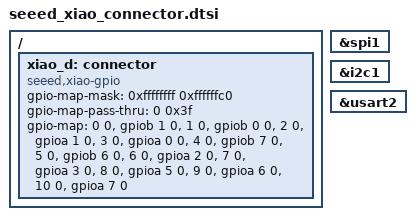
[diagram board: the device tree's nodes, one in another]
/*
 * SPDX-FileCopyrightText: Copyright (c) 2026 Perry Naseck, MIT Media Lab <pnaseck@media.mit.edu>
 * SPDX-License-Identifier: Apache-2.0
 */

/ {
	xiao_d: connector {
		compatible = "seeed,xiao-gpio";
		#gpio-cells = <2>;
		gpio-map-mask = <0xffffffff 0xffffffc0>;
		gpio-map-pass-thru = <0 0x3f>;
		gpio-map = <0 0 &gpiob 1 0>,	/* D0/A0 */
			   <1 0 &gpiob 0 0>,	/* D1/A1 */
			   <2 0 &gpioa 1 0>,	/* D2/A2 */
			   <3 0 &gpioa 0 0>,	/* D3/A3 */
			   <4 0 &gpiob 7 0>,	/* D4/SDA */
			   <5 0 &gpiob 6 0>,	/* D5/SCL */
			   <6 0 &gpioa 2 0>,	/* D6/TX */
			   <7 0 &gpioa 3 0>,	/* D7/RX */
			   <8 0 &gpioa 5 0>,	/* D8/SCK */
			   <9 0 &gpioa 6 0>,	/* D9/MISO */
			   <10 0 &gpioa 7 0>;	/* D10/MOSI */
	};
};

xiao_spi: &spi1 {};

xiao_i2c: &i2c1 {};

xiao_serial: &usart2 {};
